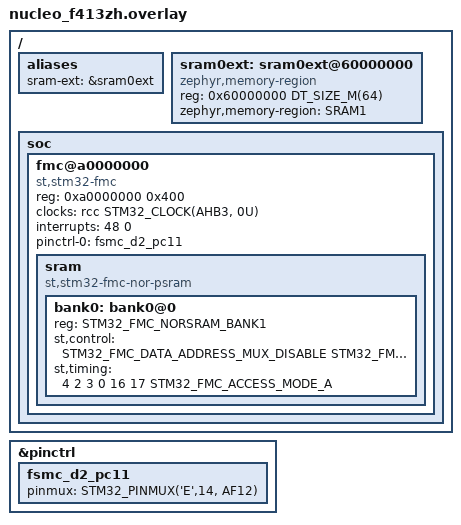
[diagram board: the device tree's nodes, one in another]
//nucleo_f413zh.overlay

#include <dt-bindings/memory-controller/stm32-fmc-nor-psram.h>

/* dummy definition - doesn't matter, this is build only */
&pinctrl {
    fsmc_d2_pc11:fsmc_d2_pc11{
        pinmux= <STM32_PINMUX('E',14, AF12)>;
    };
};

/{
    aliases {
        sram-ext = &sram0ext;
    };

    sram0ext: sram0ext@60000000 {
        compatible = "zephyr,memory-region", "mmio-sram";
        device_type = "memory";
        reg = <0x60000000 DT_SIZE_M(64)>;
        zephyr,memory-region = "SRAM1";
    };

    soc{
        fmc@a0000000 {
            compatible = "st,stm32-fmc";
            reg = <0xa0000000 0x400>;
            clocks = <&rcc STM32_CLOCK(AHB3, 0U)>;
            interrupts = < 48 0>;
            status = "okay";
            pinctrl-names = "default";
            pinctrl-0 = <&fsmc_d2_pc11>;

            sram{
                #address-cells = <1>;
                #size-cells = <0>;
                compatible = "st,stm32-fmc-nor-psram";
                status = "okay";

                bank0:bank0@0{
                    reg = <STM32_FMC_NORSRAM_BANK1>;
                    st,control = <
                    STM32_FMC_DATA_ADDRESS_MUX_DISABLE
                    STM32_FMC_MEMORY_TYPE_NOR
                    STM32_FMC_NORSRAM_MEM_BUS_WIDTH_8
                    STM32_FMC_BURST_ACCESS_MODE_DISABLE
                    STM32_FMC_WAIT_SIGNAL_POLARITY_LOW
                    STM32_FMC_WAIT_TIMING_BEFORE_WS
                    STM32_FMC_WRITE_OPERATION_ENABLE
                    STM32_FMC_WAIT_SIGNAL_DISABLE
                    STM32_FMC_EXTENDED_MODE_DISABLE
                    STM32_FMC_ASYNCHRONOUS_WAIT_DISABLE
                    STM32_FMC_WRITE_BURST_DISABLE
                    STM32_FMC_CONTINUOUS_CLOCK_SYNC_ONLY
                    STM32_FMC_WRITE_FIFO_ENABLE
                    STM32_FMC_PAGE_SIZE_NONE>;
                      st,timing = <4 2 3 0 16 17 STM32_FMC_ACCESS_MODE_A>;
                };
            };
        };
    };
};
